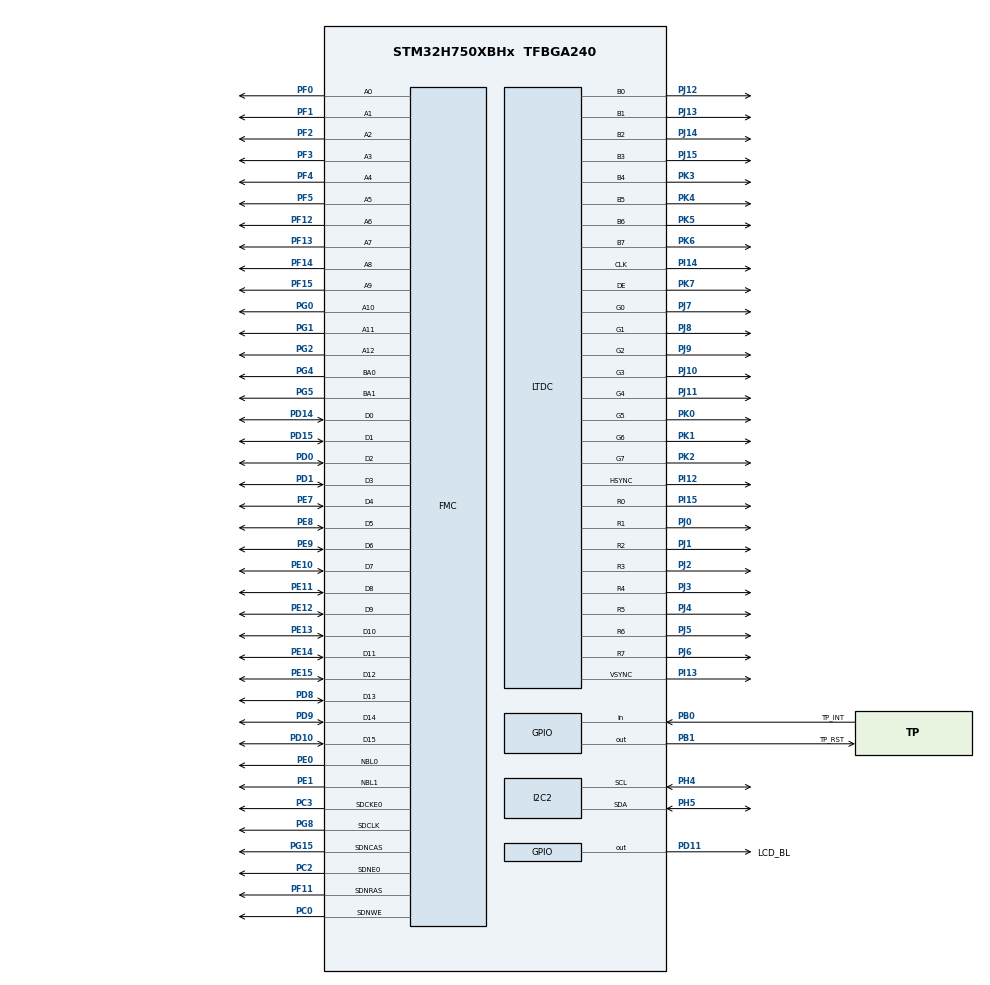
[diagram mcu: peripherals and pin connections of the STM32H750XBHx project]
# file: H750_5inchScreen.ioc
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DMA2D.ColorMode=DMA2D_OUTPUT_RGB888
FMC.CASLatency1=FMC_SDRAM_CAS_LATENCY_3
FMC.ColumnBitsNumber1=FMC_SDRAM_COLUMN_BITS_NUM_9
FMC.ExitSelfRefreshDelay1=7
FMC.LoadToActiveDelay1=2
FMC.RCDDelay1=2
FMC.RPDelay1=2
FMC.RPDelay2=2
FMC.ReadPipeDelay1=FMC_SDRAM_RPIPE_DELAY_1
FMC.ReadPipeDelay2=FMC_SDRAM_RPIPE_DELAY_1
FMC.RowCycleDelay1=7
FMC.RowCycleDelay2=7
FMC.SDClockPeriod1=FMC_SDRAM_CLOCK_PERIOD_2
FMC.SDClockPeriod2=FMC_SDRAM_CLOCK_PERIOD_2
FMC.SelfRefreshTime1=4
FMC.WriteRecoveryTime1=3
I2C2.Timing=0x307075B1
LTDC.ActiveW=800
LTDC.Alpha_L0=255
LTDC.FBStartAdress_L0=0xc0000000
LTDC.HBP=46
LTDC.HFP=40
LTDC.HSync=1
LTDC.ImageHeight_L0=480
LTDC.ImageWidth_L0=800
LTDC.Layers=0
LTDC.PixelFormat_L0=LTDC_PIXEL_FORMAT_RGB888
LTDC.VBP=23
LTDC.VFP=10
LTDC.VSync=2
LTDC.WindowX1_L0=800
LTDC.WindowY1_L0=480
Mcu.Family=STM32H7
Mcu.Name=STM32H750XBHx
Mcu.Package=TFBGA240
NVIC.DMA2D_IRQn=true\:5\:0\:true\:false\:true\:true\:true
NVIC.FMC_IRQn=true\:5\:0\:true\:false\:true\:true\:true
NVIC.LTDC_IRQn=true\:5\:0\:true\:false\:true\:true\:true
NVIC.PriorityGroup=NVIC_PRIORITYGROUP_4
PB0.GPIO_Label=TP_INT
PB0.Signal=GPIO_Input
PB1.GPIO_Label=TP_RST
PB1.PinState=GPIO_PIN_SET
PB1.Signal=GPIO_Output
PC0.Signal=FMC_SDNWE
PC2.Mode=SdramChipSelect1_1
PC2.Signal=FMC_SDNE0
PC3.Mode=SdramChipSelect1_1
PC3.Signal=FMC_SDCKE0
PD0.Signal=FMC_D2_DA2
PD1.Signal=FMC_D3_DA3
PD10.Signal=FMC_D15_DA15
PD11.GPIO_Label=LCD_BL
PD11.PinState=GPIO_PIN_SET
PD11.Signal=GPIO_Output
PD14.Signal=FMC_D0_DA0
PD15.Signal=FMC_D1_DA1
PD8.Signal=FMC_D13_DA13
PD9.Signal=FMC_D14_DA14
PE0.Signal=FMC_NBL0
PE1.Signal=FMC_NBL1
PE10.Signal=FMC_D7_DA7
PE11.Signal=FMC_D8_DA8
PE12.Signal=FMC_D9_DA9
PE13.Signal=FMC_D10_DA10
PE14.Signal=FMC_D11_DA11
PE15.Signal=FMC_D12_DA12
PE7.Signal=FMC_D4_DA4
PE8.Signal=FMC_D5_DA5
PE9.Signal=FMC_D6_DA6
PF0.Signal=FMC_A0
PF1.Signal=FMC_A1
PF11.Signal=FMC_SDNRAS
PF12.Signal=FMC_A6
PF13.Signal=FMC_A7
PF14.Signal=FMC_A8
PF15.Signal=FMC_A9
PF2.Signal=FMC_A2
PF3.Signal=FMC_A3
PF4.Signal=FMC_A4
PF5.Signal=FMC_A5
PG0.Signal=FMC_A10
PG1.Signal=FMC_A11
PG15.Signal=FMC_SDNCAS
PG2.Signal=FMC_A12
PG4.Signal=FMC_A14_BA0
PG5.Signal=FMC_A15_BA1
PG8.Signal=FMC_SDCLK
PH0-OSC_IN\ (PH0).Mode=HSE-External-Oscillator
PH0-OSC_IN\ (PH0).Signal=RCC_OSC_IN
PH1-OSC_OUT\ (PH1).Mode=HSE-External-Oscillator
PH1-OSC_OUT\ (PH1).Signal=RCC_OSC_OUT
PH4.GPIO_Pu=GPIO_PULLUP
PH4.Mode=I2C
PH4.Signal=I2C2_SCL
PH5.GPIO_Pu=GPIO_PULLUP
PH5.Mode=I2C
PH5.Signal=I2C2_SDA
PI12.GPIO_Speed=GPIO_SPEED_FREQ_HIGH
PI12.Mode=RGB888
PI12.Signal=LTDC_HSYNC
PI13.GPIO_Speed=GPIO_SPEED_FREQ_HIGH
PI13.Mode=RGB888
PI13.Signal=LTDC_VSYNC
PI14.GPIO_Speed=GPIO_SPEED_FREQ_HIGH
PI14.Mode=RGB888
PI14.Signal=LTDC_CLK
PI15.GPIO_Speed=GPIO_SPEED_FREQ_HIGH
PI15.Mode=RGB888
PI15.Signal=LTDC_R0
PJ0.GPIO_Speed=GPIO_SPEED_FREQ_HIGH
PJ0.Mode=RGB888
PJ0.Signal=LTDC_R1
PJ1.GPIO_Speed=GPIO_SPEED_FREQ_HIGH
PJ1.Mode=RGB888
PJ1.Signal=LTDC_R2
PJ10.GPIO_Speed=GPIO_SPEED_FREQ_HIGH
PJ10.Mode=RGB888
PJ10.Signal=LTDC_G3
PJ11.GPIO_Speed=GPIO_SPEED_FREQ_HIGH
PJ11.Mode=RGB888
PJ11.Signal=LTDC_G4
PJ12.GPIO_Speed=GPIO_SPEED_FREQ_HIGH
PJ12.Mode=RGB888
PJ12.Signal=LTDC_B0
PJ13.GPIO_Speed=GPIO_SPEED_FREQ_HIGH
PJ13.Mode=RGB888
PJ13.Signal=LTDC_B1
PJ14.GPIO_Speed=GPIO_SPEED_FREQ_HIGH
PJ14.Mode=RGB888
PJ14.Signal=LTDC_B2
PJ15.GPIO_Speed=GPIO_SPEED_FREQ_HIGH
PJ15.Mode=RGB888
PJ15.Signal=LTDC_B3
PJ2.GPIO_Speed=GPIO_SPEED_FREQ_HIGH
PJ2.Mode=RGB888
PJ2.Signal=LTDC_R3
PJ3.GPIO_Speed=GPIO_SPEED_FREQ_HIGH
PJ3.Mode=RGB888
PJ3.Signal=LTDC_R4
PJ4.GPIO_Speed=GPIO_SPEED_FREQ_HIGH
PJ4.Mode=RGB888
PJ4.Signal=LTDC_R5
PJ5.GPIO_Speed=GPIO_SPEED_FREQ_HIGH
PJ5.Mode=RGB888
PJ5.Signal=LTDC_R6
PJ6.GPIO_Speed=GPIO_SPEED_FREQ_HIGH
PJ6.Mode=RGB888
PJ6.Signal=LTDC_R7
PJ7.GPIO_Speed=GPIO_SPEED_FREQ_HIGH
PJ7.Mode=RGB888
PJ7.Signal=LTDC_G0
PJ8.GPIO_Speed=GPIO_SPEED_FREQ_HIGH
PJ8.Mode=RGB888
PJ8.Signal=LTDC_G1
PJ9.GPIO_Speed=GPIO_SPEED_FREQ_HIGH
PJ9.Mode=RGB888
PJ9.Signal=LTDC_G2
PK0.GPIO_Speed=GPIO_SPEED_FREQ_HIGH
PK0.Mode=RGB888
PK0.Signal=LTDC_G5
PK1.GPIO_Speed=GPIO_SPEED_FREQ_HIGH
PK1.Mode=RGB888
PK1.Signal=LTDC_G6
PK2.GPIO_Speed=GPIO_SPEED_FREQ_HIGH
PK2.Mode=RGB888
PK2.Signal=LTDC_G7
PK3.GPIO_Speed=GPIO_SPEED_FREQ_HIGH
PK3.Mode=RGB888
PK3.Signal=LTDC_B4
PK4.GPIO_Speed=GPIO_SPEED_FREQ_HIGH
PK4.Mode=RGB888
PK4.Signal=LTDC_B5
PK5.GPIO_Speed=GPIO_SPEED_FREQ_HIGH
PK5.Mode=RGB888
PK5.Signal=LTDC_B6
PK6.GPIO_Speed=GPIO_SPEED_FREQ_HIGH
PK6.Mode=RGB888
PK6.Signal=LTDC_B7
PK7.GPIO_Speed=GPIO_SPEED_FREQ_HIGH
PK7.Mode=RGB888
PK7.Signal=LTDC_DE
ProjectManager.HeapSize=0x200
ProjectManager.StackSize=0x400
ProjectManager.TargetToolchain=MDK-ARM V5.27
RCC.ADCFreq_Value=50390625
RCC.APB1Freq_Value=120000000
RCC.APB2Freq_Value=120000000
RCC.APB3Freq_Value=120000000
RCC.APB4Freq_Value=120000000
RCC.CortexFreq_Value=480000000
RCC.D1PPRE=RCC_APB3_DIV2
RCC.D2PPRE1=RCC_APB1_DIV2
RCC.D2PPRE2=RCC_APB2_DIV2
RCC.D3PPRE=RCC_APB4_DIV2
RCC.DIVM1=5
RCC.DIVM3=3
RCC.DIVN1=192
RCC.DIVN3=51
RCC.DIVR3=25
RCC.HCLKFreq_Value=240000000
RCC.HPRE=RCC_HCLK_DIV2
RCC.PLL2FRACN=0
RCC.PLL3FRACN=0
RCC.PLLFRACN=0
RCC.PLLSourceVirtual=RCC_PLLSOURCE_HSE
RCC.SYSCLKFreq_VALUE=480000000
RCC.SYSCLKSource=RCC_SYSCLKSOURCE_PLLCLK
RCC.USBFreq_Value=480000000
SH.FMC_A0.0=FMC_A0,13b-sda1
SH.FMC_A1.0=FMC_A1,13b-sda1
SH.FMC_A10.0=FMC_A10,13b-sda1
SH.FMC_A11.0=FMC_A11,13b-sda1
SH.FMC_A12.0=FMC_A12,13b-sda1
SH.FMC_A14_BA0.0=FMC_BA0,FourSdramBanks1
SH.FMC_A15_BA1.0=FMC_BA1,FourSdramBanks1
SH.FMC_A2.0=FMC_A2,13b-sda1
SH.FMC_A3.0=FMC_A3,13b-sda1
SH.FMC_A4.0=FMC_A4,13b-sda1
SH.FMC_A5.0=FMC_A5,13b-sda1
SH.FMC_A6.0=FMC_A6,13b-sda1
SH.FMC_A7.0=FMC_A7,13b-sda1
SH.FMC_A8.0=FMC_A8,13b-sda1
SH.FMC_A9.0=FMC_A9,13b-sda1
SH.FMC_D0_DA0.0=FMC_D0,sd-16b-d1
SH.FMC_D10_DA10.0=FMC_D10,sd-16b-d1
SH.FMC_D11_DA11.0=FMC_D11,sd-16b-d1
SH.FMC_D12_DA12.0=FMC_D12,sd-16b-d1
SH.FMC_D13_DA13.0=FMC_D13,sd-16b-d1
SH.FMC_D14_DA14.0=FMC_D14,sd-16b-d1
SH.FMC_D15_DA15.0=FMC_D15,sd-16b-d1
SH.FMC_D1_DA1.0=FMC_D1,sd-16b-d1
SH.FMC_D2_DA2.0=FMC_D2,sd-16b-d1
SH.FMC_D3_DA3.0=FMC_D3,sd-16b-d1
SH.FMC_D4_DA4.0=FMC_D4,sd-16b-d1
SH.FMC_D5_DA5.0=FMC_D5,sd-16b-d1
SH.FMC_D6_DA6.0=FMC_D6,sd-16b-d1
SH.FMC_D7_DA7.0=FMC_D7,sd-16b-d1
SH.FMC_D8_DA8.0=FMC_D8,sd-16b-d1
SH.FMC_D9_DA9.0=FMC_D9,sd-16b-d1
SH.FMC_NBL0.0=FMC_NBL0,Sd2ByteEnable1
SH.FMC_NBL1.0=FMC_NBL1,Sd2ByteEnable1
SH.FMC_SDCLK.0=FMC_SDCLK,13b-sda1
SH.FMC_SDNCAS.0=FMC_SDNCAS,13b-sda1
SH.FMC_SDNRAS.0=FMC_SDNRAS,13b-sda1
SH.FMC_SDNWE.0=FMC_SDNWE,13b-sda1
VP_DMA2D_VS_DMA2D.Mode=DMA2D_Activate
board=custom

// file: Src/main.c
/* USER CODE BEGIN Header */
/**
  ******************************************************************************
  * @file           : main.c
  * @brief          : Main program body
  ******************************************************************************
  * @attention
  *
  * <h2><center>&copy; Copyright (c) 2022 STMicroelectronics.
  * All rights reserved.</center></h2>
  *
  * This software component is licensed by ST under BSD 3-Clause license,
  * the "License"; You may not use this file except in compliance with the
  * License. You may obtain a copy of the License at:
  *                        opensource.org/licenses/BSD-3-Clause
  *
  ******************************************************************************
  */
/* USER CODE END Header */
#include "main.h"

/* USER CODE BEGIN Includes */
#include "bsp_sdram.h"
#include "lvgl.h"
#include "lv_port_disp.h"
#include "lv_port_indev.h"
/* USER CODE END Includes */

DMA2D_HandleTypeDef hdma2d;

I2C_HandleTypeDef hi2c2;

LTDC_HandleTypeDef hltdc;

SDRAM_HandleTypeDef hsdram1;

void SystemClock_Config(void);
static void MX_GPIO_Init(void);
static void MX_DMA2D_Init(void);
static void MX_FMC_Init(void);
static void MX_I2C2_Init(void);
static void MX_LTDC_Init(void);

/* USER CODE BEGIN 0 */
volatile HAL_LTDC_StateTypeDef LtdcState;
lv_obj_t *src;
lv_style_t objStyle;

void lv_example_arc_1(void)
{
    /*Create an Arc*/
    lv_obj_t * arc = lv_arc_create(lv_scr_act());
    lv_obj_set_size(arc, 150, 150);
    lv_arc_set_rotation(arc, 135);
    lv_arc_set_bg_angles(arc, 0, 270);
    lv_arc_set_value(arc, 40);
    lv_obj_center(arc);
}
/* USER CODE END 0 */

int main(void)
{
  /* USER CODE BEGIN 1 */
	uint32_t uiTick100ms;
	TS_StateTypeDef tpState;
  /* USER CODE END 1 */

  /* MCU Configuration--------------------------------------------------------*/

  /* Reset of all peripherals, Initializes the Flash interface and the Systick. */
  HAL_Init();

  /* Configure the system clock */
  SystemClock_Config();

  /* Initialize all configured peripherals */
  MX_GPIO_Init();
  MX_DMA2D_Init();
  MX_FMC_Init();
  MX_I2C2_Init();
  MX_LTDC_Init();
  /* USER CODE BEGIN 2 */
  SDRAM_Init();
  memset((uint8_t *)0xc0000000, 0xFF, 1843200);
//  gt911_init();
  lv_init();
  lv_port_disp_init();
  lv_port_indev_init();
//  src = lv_obj_create(lv_scr_act());
//  lv_obj_set_size(src, 800, 480);
//  lv_style_init(&objStyle);
//  lv_style_set_bg_color(&objStyle, lv_color_hex(0xff0000));
//  lv_obj_add_style(src, &objStyle, 0);
  lv_example_arc_1();
  uiTick100ms = uwTick;
  /* USER CODE END 2 */

  /* Infinite loop */
  /* USER CODE BEGIN WHILE */
  while (1)
  {
	  lv_timer_handler();
//	  if((uint32_t)(uwTick - uiTick100ms) >= 100)
//	  {
//		  uiTick100ms = uwTick;
//		  gt911_get_state(&tpState);
//	  }
    /* USER CODE END WHILE */

  }
}

void SystemClock_Config(void)
{
  RCC_OscInitTypeDef RCC_OscInitStruct = {0};
  RCC_ClkInitTypeDef RCC_ClkInitStruct = {0};

  /** Supply configuration update enable
  */
  HAL_PWREx_ConfigSupply(PWR_LDO_SUPPLY);
  /** Configure the main internal regulator output voltage
  */
  __HAL_PWR_VOLTAGESCALING_CONFIG(PWR_REGULATOR_VOLTAGE_SCALE0);

  while(!__HAL_PWR_GET_FLAG(PWR_FLAG_VOSRDY)) {}
  /** Macro to configure the PLL clock source
  */
  __HAL_RCC_PLL_PLLSOURCE_CONFIG(RCC_PLLSOURCE_HSE);
  /** Initializes the RCC Oscillators according to the specified parameters
  * in the RCC_OscInitTypeDef structure.
  */
  RCC_OscInitStruct.OscillatorType = RCC_OSCILLATORTYPE_HSE;
  RCC_OscInitStruct.HSEState = RCC_HSE_ON;
  RCC_OscInitStruct.PLL.PLLState = RCC_PLL_ON;
  RCC_OscInitStruct.PLL.PLLSource = RCC_PLLSOURCE_HSE;
  RCC_OscInitStruct.PLL.PLLM = 5;
  RCC_OscInitStruct.PLL.PLLN = 192;
  RCC_OscInitStruct.PLL.PLLP = 2;
  RCC_OscInitStruct.PLL.PLLQ = 2;
  RCC_OscInitStruct.PLL.PLLR = 2;
  RCC_OscInitStruct.PLL.PLLRGE = RCC_PLL1VCIRANGE_2;
  RCC_OscInitStruct.PLL.PLLVCOSEL = RCC_PLL1VCOWIDE;
  RCC_OscInitStruct.PLL.PLLFRACN = 0;
  if (HAL_RCC_OscConfig(&RCC_OscInitStruct) != HAL_OK)
  {
    Error_Handler();
  }
  /** Initializes the CPU, AHB and APB buses clocks
  */
  RCC_ClkInitStruct.ClockType = RCC_CLOCKTYPE_HCLK|RCC_CLOCKTYPE_SYSCLK
                              |RCC_CLOCKTYPE_PCLK1|RCC_CLOCKTYPE_PCLK2
                              |RCC_CLOCKTYPE_D3PCLK1|RCC_CLOCKTYPE_D1PCLK1;
  RCC_ClkInitStruct.SYSCLKSource = RCC_SYSCLKSOURCE_PLLCLK;
  RCC_ClkInitStruct.SYSCLKDivider = RCC_SYSCLK_DIV1;
  RCC_ClkInitStruct.AHBCLKDivider = RCC_HCLK_DIV2;
  RCC_ClkInitStruct.APB3CLKDivider = RCC_APB3_DIV2;
  RCC_ClkInitStruct.APB1CLKDivider = RCC_APB1_DIV2;
  RCC_ClkInitStruct.APB2CLKDivider = RCC_APB2_DIV2;
  RCC_ClkInitStruct.APB4CLKDivider = RCC_APB4_DIV2;

  if (HAL_RCC_ClockConfig(&RCC_ClkInitStruct, FLASH_LATENCY_4) != HAL_OK)
  {
    Error_Handler();
  }
}

static void MX_DMA2D_Init(void)
{

  hdma2d.Instance = DMA2D;
  hdma2d.Init.Mode = DMA2D_M2M;
  hdma2d.Init.ColorMode = DMA2D_OUTPUT_RGB888;
  hdma2d.Init.OutputOffset = 0;
  hdma2d.LayerCfg[1].InputOffset = 0;
  hdma2d.LayerCfg[1].InputColorMode = DMA2D_INPUT_RGB888;
  hdma2d.LayerCfg[1].AlphaMode = DMA2D_NO_MODIF_ALPHA;
  hdma2d.LayerCfg[1].InputAlpha = 0;
  hdma2d.LayerCfg[1].AlphaInverted = DMA2D_REGULAR_ALPHA;
  hdma2d.LayerCfg[1].RedBlueSwap = DMA2D_RB_REGULAR;
  hdma2d.LayerCfg[1].ChromaSubSampling = DMA2D_NO_CSS;
  if (HAL_DMA2D_Init(&hdma2d) != HAL_OK)
  {
    Error_Handler();
  }
  if (HAL_DMA2D_ConfigLayer(&hdma2d, 1) != HAL_OK)
  {
    Error_Handler();
  }

}

static void MX_I2C2_Init(void)
{

  hi2c2.Instance = I2C2;
  hi2c2.Init.Timing = 0x307075B1;
  hi2c2.Init.OwnAddress1 = 0;
  hi2c2.Init.AddressingMode = I2C_ADDRESSINGMODE_7BIT;
  hi2c2.Init.DualAddressMode = I2C_DUALADDRESS_DISABLE;
  hi2c2.Init.OwnAddress2 = 0;
  hi2c2.Init.OwnAddress2Masks = I2C_OA2_NOMASK;
  hi2c2.Init.GeneralCallMode = I2C_GENERALCALL_DISABLE;
  hi2c2.Init.NoStretchMode = I2C_NOSTRETCH_DISABLE;
  if (HAL_I2C_Init(&hi2c2) != HAL_OK)
  {
    Error_Handler();
  }
  /** Configure Analogue filter
  */
  if (HAL_I2CEx_ConfigAnalogFilter(&hi2c2, I2C_ANALOGFILTER_ENABLE) != HAL_OK)
  {
    Error_Handler();
  }
  /** Configure Digital filter
  */
  if (HAL_I2CEx_ConfigDigitalFilter(&hi2c2, 0) != HAL_OK)
  {
    Error_Handler();
  }

}

static void MX_LTDC_Init(void)
{

  LTDC_LayerCfgTypeDef pLayerCfg = {0};

  hltdc.Instance = LTDC;
  hltdc.Init.HSPolarity = LTDC_HSPOLARITY_AL;
  hltdc.Init.VSPolarity = LTDC_VSPOLARITY_AL;
  hltdc.Init.DEPolarity = LTDC_DEPOLARITY_AL;
  hltdc.Init.PCPolarity = LTDC_PCPOLARITY_IPC;
  hltdc.Init.HorizontalSync = 0;
  hltdc.Init.VerticalSync = 1;
  hltdc.Init.AccumulatedHBP = 46;
  hltdc.Init.AccumulatedVBP = 24;
  hltdc.Init.AccumulatedActiveW = 846;
  hltdc.Init.AccumulatedActiveH = 504;
  hltdc.Init.TotalWidth = 886;
  hltdc.Init.TotalHeigh = 514;
  hltdc.Init.Backcolor.Blue = 0;
  hltdc.Init.Backcolor.Green = 0;
  hltdc.Init.Backcolor.Red = 0;
  if (HAL_LTDC_Init(&hltdc) != HAL_OK)
  {
    Error_Handler();
  }
  pLayerCfg.WindowX0 = 0;
  pLayerCfg.WindowX1 = 800;
  pLayerCfg.WindowY0 = 0;
  pLayerCfg.WindowY1 = 480;
  pLayerCfg.PixelFormat = LTDC_PIXEL_FORMAT_RGB888;
  pLayerCfg.Alpha = 255;
  pLayerCfg.Alpha0 = 0;
  pLayerCfg.BlendingFactor1 = LTDC_BLENDING_FACTOR1_CA;
  pLayerCfg.BlendingFactor2 = LTDC_BLENDING_FACTOR2_CA;
  pLayerCfg.FBStartAdress = 0xc0000000;
  pLayerCfg.ImageWidth = 800;
  pLayerCfg.ImageHeight = 480;
  pLayerCfg.Backcolor.Blue = 0;
  pLayerCfg.Backcolor.Green = 0;
  pLayerCfg.Backcolor.Red = 0;
  if (HAL_LTDC_ConfigLayer(&hltdc, &pLayerCfg, 0) != HAL_OK)
  {
    Error_Handler();
  }
  /* USER CODE BEGIN LTDC_Init 2 */
//	hltdc.Init.Backcolor.Blue = 0;
//	hltdc.Init.Backcolor.Red = 255;
//	hltdc.Init.Backcolor.Green = 0;

  /* USER CODE END LTDC_Init 2 */

}

/* FMC initialization function */
static void MX_FMC_Init(void)
{

  FMC_SDRAM_TimingTypeDef SdramTiming = {0};

  /** Perform the SDRAM1 memory initialization sequence
  */
  hsdram1.Instance = FMC_SDRAM_DEVICE;
  /* hsdram1.Init */
  hsdram1.Init.SDBank = FMC_SDRAM_BANK1;
  hsdram1.Init.ColumnBitsNumber = FMC_SDRAM_COLUMN_BITS_NUM_9;
  hsdram1.Init.RowBitsNumber = FMC_SDRAM_ROW_BITS_NUM_13;
  hsdram1.Init.MemoryDataWidth = FMC_SDRAM_MEM_BUS_WIDTH_16;
  hsdram1.Init.InternalBankNumber = FMC_SDRAM_INTERN_BANKS_NUM_4;
  hsdram1.Init.CASLatency = FMC_SDRAM_CAS_LATENCY_3;
  hsdram1.Init.WriteProtection = FMC_SDRAM_WRITE_PROTECTION_DISABLE;
  hsdram1.Init.SDClockPeriod = FMC_SDRAM_CLOCK_PERIOD_2;
  hsdram1.Init.ReadBurst = FMC_SDRAM_RBURST_DISABLE;
  hsdram1.Init.ReadPipeDelay = FMC_SDRAM_RPIPE_DELAY_1;
  /* SdramTiming */
  SdramTiming.LoadToActiveDelay = 2;
  SdramTiming.ExitSelfRefreshDelay = 7;
  SdramTiming.SelfRefreshTime = 4;
  SdramTiming.RowCycleDelay = 7;
  SdramTiming.WriteRecoveryTime = 3;
  SdramTiming.RPDelay = 2;
  SdramTiming.RCDDelay = 2;

  if (HAL_SDRAM_Init(&hsdram1, &SdramTiming) != HAL_OK)
  {
    Error_Handler( );
  }

}

static void MX_GPIO_Init(void)
{
  GPIO_InitTypeDef GPIO_InitStruct = {0};

  /* GPIO Ports Clock Enable */
  __HAL_RCC_GPIOK_CLK_ENABLE();
  __HAL_RCC_GPIOE_CLK_ENABLE();
  __HAL_RCC_GPIOJ_CLK_ENABLE();
  __HAL_RCC_GPIOG_CLK_ENABLE();
  __HAL_RCC_GPIOD_CLK_ENABLE();
  __HAL_RCC_GPIOF_CLK_ENABLE();
  __HAL_RCC_GPIOI_CLK_ENABLE();
  __HAL_RCC_GPIOH_CLK_ENABLE();
  __HAL_RCC_GPIOC_CLK_ENABLE();
  __HAL_RCC_GPIOB_CLK_ENABLE();

  /*Configure GPIO pin Output Level */
  HAL_GPIO_WritePin(LCD_BL_GPIO_Port, LCD_BL_Pin, GPIO_PIN_SET);

  /*Configure GPIO pin Output Level */
  HAL_GPIO_WritePin(TP_RST_GPIO_Port, TP_RST_Pin, GPIO_PIN_SET);

  /*Configure GPIO pin : LCD_BL_Pin */
  GPIO_InitStruct.Pin = LCD_BL_Pin;
  GPIO_InitStruct.Mode = GPIO_MODE_OUTPUT_PP;
  GPIO_InitStruct.Pull = GPIO_NOPULL;
  GPIO_InitStruct.Speed = GPIO_SPEED_FREQ_LOW;
  HAL_GPIO_Init(LCD_BL_GPIO_Port, &GPIO_InitStruct);

  /*Configure GPIO pin : TP_RST_Pin */
  GPIO_InitStruct.Pin = TP_RST_Pin;
  GPIO_InitStruct.Mode = GPIO_MODE_OUTPUT_PP;
  GPIO_InitStruct.Pull = GPIO_NOPULL;
  GPIO_InitStruct.Speed = GPIO_SPEED_FREQ_LOW;
  HAL_GPIO_Init(TP_RST_GPIO_Port, &GPIO_InitStruct);

  /*Configure GPIO pin : TP_INT_Pin */
  GPIO_InitStruct.Pin = TP_INT_Pin;
  GPIO_InitStruct.Mode = GPIO_MODE_INPUT;
  GPIO_InitStruct.Pull = GPIO_NOPULL;
  HAL_GPIO_Init(TP_INT_GPIO_Port, &GPIO_InitStruct);

}

void Error_Handler(void)
{
  __disable_irq();
  while (1)
  {
  }
}

/************************ (C) COPYRIGHT STMicroelectronics *****END OF FILE****/
